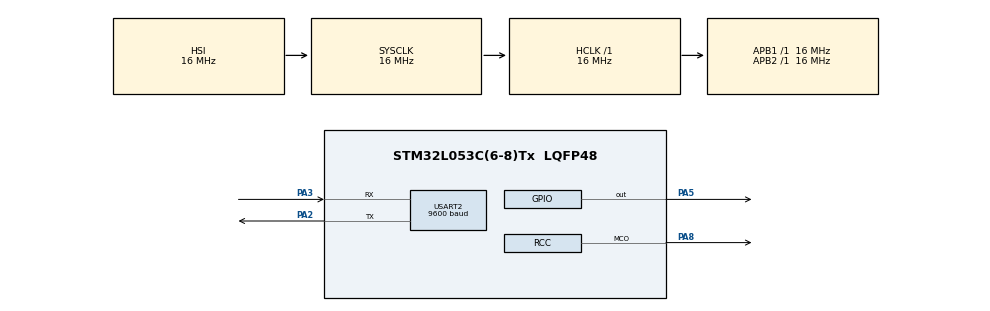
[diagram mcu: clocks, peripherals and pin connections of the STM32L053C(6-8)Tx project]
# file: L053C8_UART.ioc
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Mcu.Family=STM32L0
Mcu.Name=STM32L053C(6-8)Tx
Mcu.Package=LQFP48
PA13.Mode=Serial_Wire
PA13.Signal=SYS_SWDIO
PA14.Mode=Serial_Wire
PA14.Signal=SYS_SWCLK
PA2.Mode=Asynchronous
PA2.Signal=USART2_TX
PA3.Mode=Asynchronous
PA3.Signal=USART2_RX
PA5.Signal=GPIO_Output
PA8.Mode=Clock-out
PA8.Signal=RCC_MCO
ProjectManager.HeapSize=0x200
ProjectManager.StackSize=0x400
ProjectManager.TargetToolchain=SW4STM32
RCC.AHBFreq_Value=16000000
RCC.APB1Freq_Value=16000000
RCC.APB1TimFreq_Value=16000000
RCC.APB2Freq_Value=16000000
RCC.APB2TimFreq_Value=16000000
RCC.HCLKFreq_Value=16000000
RCC.HSE_VALUE=8000000
RCC.HSI16_VALUE=16000000
RCC.HSI48_VALUE=48000000
RCC.HSI_VALUE=16000000
RCC.LSE_VALUE=32768
RCC.MSI_VALUE=2097000
RCC.SYSCLKFreq_VALUE=16000000
RCC.SYSCLKSource=RCC_SYSCLKSOURCE_HSI
RCC.VCOOutputFreq_Value=48000000
USART2.BaudRate=9600
USART2.WordLength=UART_WORDLENGTH_8B
board=L053C8_UART

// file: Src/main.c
/**
  ******************************************************************************
  * File Name          : main.c
  * Description        : Main program body
  ******************************************************************************
  *
  * COPYRIGHT(c) 2016 STMicroelectronics
  *
  * Redistribution and use in source and binary forms, with or without modification,
  * are permitted provided that the following conditions are met:
  *   1. Redistributions of source code must retain the above copyright notice,
  *      this list of conditions and the following disclaimer.
  *   2. Redistributions in binary form must reproduce the above copyright notice,
  *      this list of conditions and the following disclaimer in the documentation
  *      and/or other materials provided with the distribution.
  *   3. Neither the name of STMicroelectronics nor the names of its contributors
  *      may be used to endorse or promote products derived from this software
  *      without specific prior written permission.
  *
  * THIS SOFTWARE IS PROVIDED BY THE COPYRIGHT HOLDERS AND CONTRIBUTORS "AS IS"
  * AND ANY EXPRESS OR IMPLIED WARRANTIES, INCLUDING, BUT NOT LIMITED TO, THE
  * IMPLIED WARRANTIES OF MERCHANTABILITY AND FITNESS FOR A PARTICULAR PURPOSE ARE
  * DISCLAIMED. IN NO EVENT SHALL THE COPYRIGHT HOLDER OR CONTRIBUTORS BE LIABLE
  * FOR ANY DIRECT, INDIRECT, INCIDENTAL, SPECIAL, EXEMPLARY, OR CONSEQUENTIAL
  * DAMAGES (INCLUDING, BUT NOT LIMITED TO, PROCUREMENT OF SUBSTITUTE GOODS OR
  * SERVICES; LOSS OF USE, DATA, OR PROFITS; OR BUSINESS INTERRUPTION) HOWEVER
  * CAUSED AND ON ANY THEORY OF LIABILITY, WHETHER IN CONTRACT, STRICT LIABILITY,
  * OR TORT (INCLUDING NEGLIGENCE OR OTHERWISE) ARISING IN ANY WAY OUT OF THE USE
  * OF THIS SOFTWARE, EVEN IF ADVISED OF THE POSSIBILITY OF SUCH DAMAGE.
  *
  ******************************************************************************
  */
#include "main.h"
#include "stm32l0xx_hal.h"
#include "usart.h"
#include "gpio.h"
#include "string.h"

/* USER CODE BEGIN PV */
/* Private variables ---------------------------------------------------------*/

/* USER CODE END PV */

void SystemClock_Config(void);
void Error_Handler(void);

/* USER CODE BEGIN PFP */
/* Private function prototypes -----------------------------------------------*/

/* USER CODE END PFP */

/* USER CODE BEGIN 0 */
/* Buffer used for transmission on USART2 */
char tx2_buffer[80];

int count = 0;

/* USER CODE END 0 */

int main(void)
{

  /* MCU Configuration----------------------------------------------------------*/

  /* Reset of all peripherals, Initializes the Flash interface and the Systick. */
  HAL_Init();

  /* Configure the system clock */
  SystemClock_Config();

  /* Initialize all configured peripherals */
  MX_GPIO_Init();
  MX_USART2_UART_Init();

  /* Infinite loop */
  while (1)
  {

  /* USER CODE BEGIN 3 */

      HAL_GPIO_TogglePin(GPIOA, GPIO_PIN_5);

      sprintf(tx2_buffer, "Count is %d\n", count);
      HAL_UART_Transmit(&huart2, (uint8_t*)tx2_buffer,  strlen(tx2_buffer), 5000);
      HAL_Delay(1000);

      count++;

  }
  /* USER CODE END 3 */

}

/** System Clock Configuration
*/
void SystemClock_Config(void)
{

  RCC_OscInitTypeDef RCC_OscInitStruct;
  RCC_ClkInitTypeDef RCC_ClkInitStruct;
  RCC_PeriphCLKInitTypeDef PeriphClkInit;

    /**Configure the main internal regulator output voltage
    */
  __HAL_PWR_VOLTAGESCALING_CONFIG(PWR_REGULATOR_VOLTAGE_SCALE1);

    /**Initializes the CPU, AHB and APB busses clocks
    */
  RCC_OscInitStruct.OscillatorType = RCC_OSCILLATORTYPE_HSI;
  RCC_OscInitStruct.HSIState = RCC_HSI_ON;
  RCC_OscInitStruct.HSICalibrationValue = 16;
  RCC_OscInitStruct.PLL.PLLState = RCC_PLL_NONE;
  if (HAL_RCC_OscConfig(&RCC_OscInitStruct) != HAL_OK)
  {
    Error_Handler();
  }

    /**Initializes the CPU, AHB and APB busses clocks
    */
  RCC_ClkInitStruct.ClockType = RCC_CLOCKTYPE_HCLK|RCC_CLOCKTYPE_SYSCLK
                              |RCC_CLOCKTYPE_PCLK1|RCC_CLOCKTYPE_PCLK2;
  RCC_ClkInitStruct.SYSCLKSource = RCC_SYSCLKSOURCE_HSI;
  RCC_ClkInitStruct.AHBCLKDivider = RCC_SYSCLK_DIV1;
  RCC_ClkInitStruct.APB1CLKDivider = RCC_HCLK_DIV1;
  RCC_ClkInitStruct.APB2CLKDivider = RCC_HCLK_DIV1;

  if (HAL_RCC_ClockConfig(&RCC_ClkInitStruct, FLASH_LATENCY_0) != HAL_OK)
  {
    Error_Handler();
  }

  PeriphClkInit.PeriphClockSelection = RCC_PERIPHCLK_USART2;
  PeriphClkInit.Usart2ClockSelection = RCC_USART2CLKSOURCE_PCLK1;
  if (HAL_RCCEx_PeriphCLKConfig(&PeriphClkInit) != HAL_OK)
  {
    Error_Handler();
  }

  HAL_RCC_MCOConfig(RCC_MCO1, RCC_MCO1SOURCE_SYSCLK, RCC_MCODIV_1);

    /**Configure the Systick interrupt time
    */
  HAL_SYSTICK_Config(HAL_RCC_GetHCLKFreq()/1000);

    /**Configure the Systick
    */
  HAL_SYSTICK_CLKSourceConfig(SYSTICK_CLKSOURCE_HCLK);

  /* SysTick_IRQn interrupt configuration */
  HAL_NVIC_SetPriority(SysTick_IRQn, 0, 0);
}

void Error_Handler(void)
{
  while(1)
  {
  }
}

/************************ (C) COPYRIGHT STMicroelectronics *****END OF FILE****/
